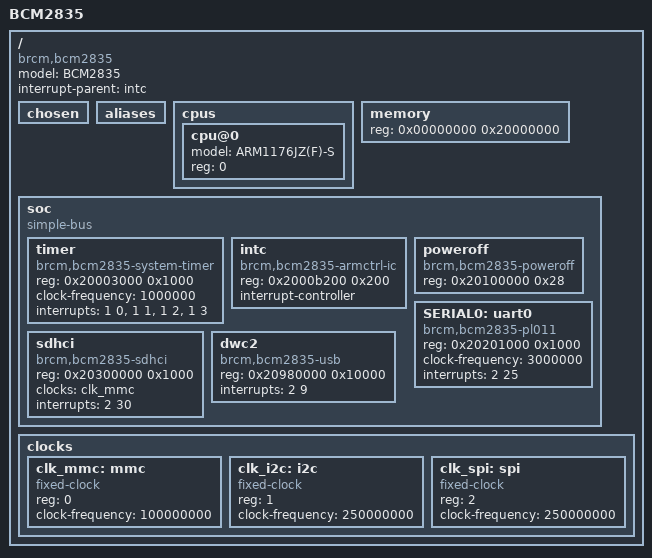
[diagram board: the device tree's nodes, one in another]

/ {
	#address-cells = <1>;
	#size-cells = <1>;
	compatible = "brcm,bcm2835";
	model = "BCM2835";
	interrupt-parent = <&intc>;

	chosen { };
	aliases { };

	cpus {
		#address-cells = <1>;
		#size-cells = <0>;

		cpu@0 {
			device_type = "cpu";
			model = "ARM1176JZ(F)-S";
			reg = <0>;
		};
	};

	memory { 
		device_type = "memory"; 
		reg = <0x00000000 0x20000000>; /* 512 MB */
	};

	soc {
		#address-cells = <1>;
		#size-cells = <1>;
		compatible = "simple-bus";

		timer {
			compatible = "brcm,bcm2835-system-timer";
			reg = <0x20003000 0x1000>;
			clock-frequency = <1000000>;
			interrupts = <1 0>, <1 1>, <1 2>, <1 3>;
		};

		intc: intc {
			compatible = "brcm,bcm2835-armctrl-ic";
			reg = <0x2000b200 0x200>;
			interrupt-controller;
			#interrupt-cells = <2>;
		};

		poweroff {
			compatible = "brcm,bcm2835-poweroff";
			reg = <0x20100000 0x28>;
		};

		SERIAL0: uart0 {
	      		compatible = "brcm,bcm2835-pl011", "arm,pl011";
	      		reg = <0x20201000 0x1000>;
			clock-frequency = <3000000>;
			interrupts = <2 25>;
		};

		sdhci {
			compatible = "brcm,bcm2835-sdhci";
			reg = <0x20300000 0x1000>;
			clocks = <&clk_mmc>;
			interrupts = <2 30>;
		};

		dwc2 {
			compatible = "brcm,bcm2835-usb";
			reg = <0x20980000 0x10000>;
			interrupts = <2 9>;
		};
	};

	clocks {
		#address-cells = <1>;
		#size-cells = <0>;

		clk_mmc: mmc {
			compatible = "fixed-clock";
			reg = <0>;
			#clock-cells = <0>;
			clock-frequency = <100000000>;
		};

		clk_i2c: i2c {
			compatible = "fixed-clock";
			reg = <1>;
			#clock-cells = <0>;
			clock-frequency = <250000000>;
		};

		clk_spi: spi {
			compatible = "fixed-clock";
			reg = <2>;
			#clock-cells = <0>;
			clock-frequency = <250000000>;
		};
	};
};
